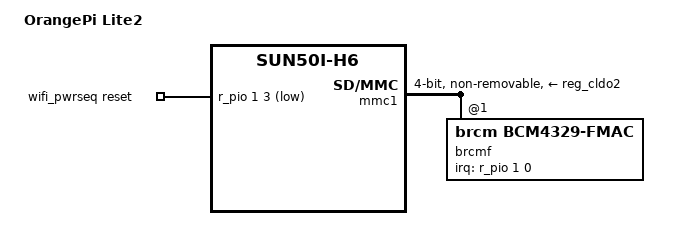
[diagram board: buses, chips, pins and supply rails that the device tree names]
// SPDX-License-Identifier: (GPL-2.0+ or MIT)
/*
 * Copyright (C) 2018 Jagan Teki <jagan@openedev.com>
 */

#include "sun50i-h6-orangepi.dtsi"

/ {
	model = "OrangePi Lite2";
	compatible = "xunlong,orangepi-lite2", "allwinner,sun50i-h6";

	wifi_pwrseq: wifi-pwrseq {
		compatible = "mmc-pwrseq-simple";
		clocks = <&rtc 1>;
		clock-names = "ext_clock";
		reset-gpios = <&r_pio 1 3 GPIO_ACTIVE_LOW>; /* WL-REG-ON: PM3 */
		post-power-on-delay-ms = <200>;
	};
};

&mmc1 {
	pinctrl-names = "default";
	pinctrl-0 = <&mmc1_pins>;
	vmmc-supply = <&reg_cldo2>;
	vqmmc-supply = <&reg_bldo3>;
	mmc-pwrseq = <&wifi_pwrseq>;
	bus-width = <4>;
	non-removable;
	status = "okay";

	brcmf: wifi@1 {
		reg = <1>;
		compatible = "brcm,bcm4329-fmac";
		interrupt-parent = <&r_pio>;
		interrupts = <1 0 IRQ_TYPE_LEVEL_LOW>;	/* WL-WAKE-AP: PM0 */
		interrupt-names = "host-wake";
	};
};
